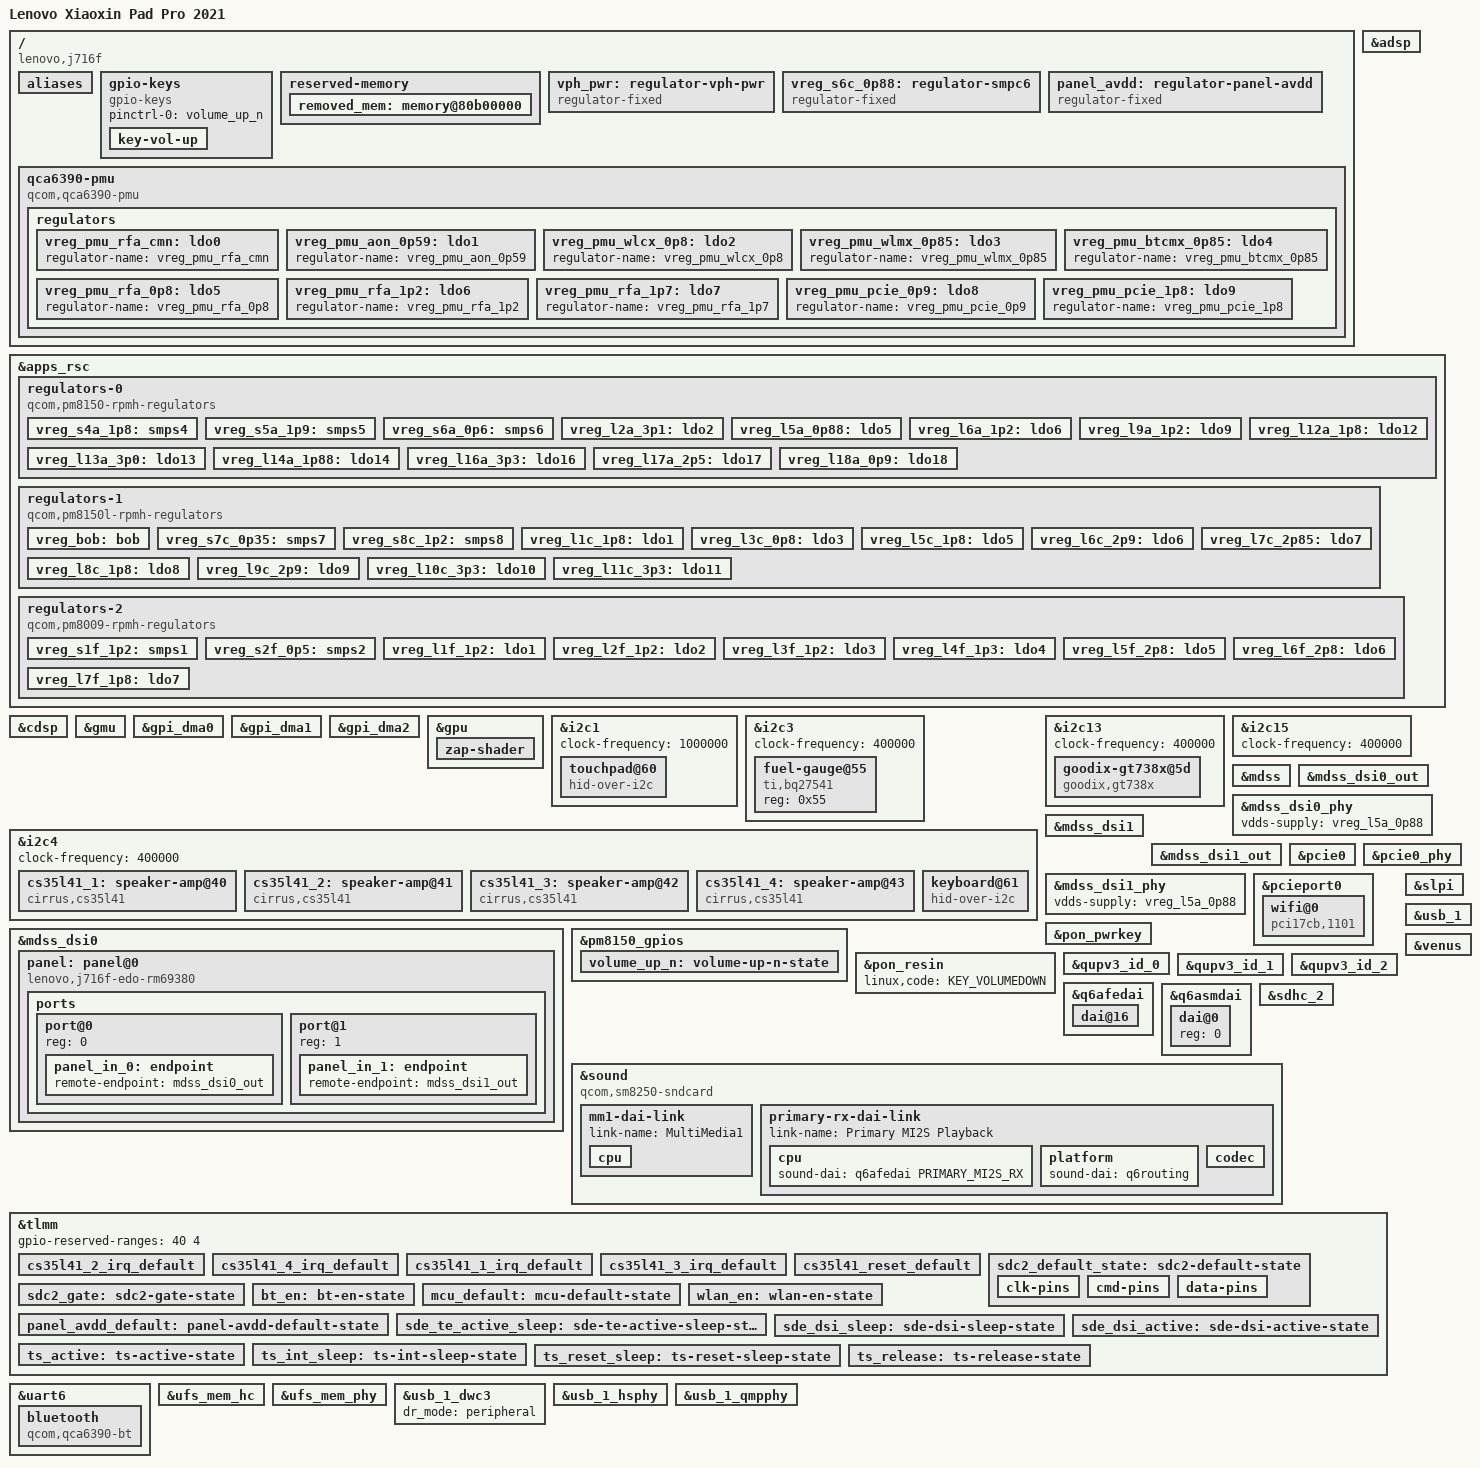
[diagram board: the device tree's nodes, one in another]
// SPDX-License-Identifier: GPL-2.0-only
/*
 * Copyright (c) 2025, David Wronek <david@mainlining.org>
 */

/dts-v1/;

#include <dt-bindings/arm/qcom,ids.h>
#include <dt-bindings/gpio/gpio.h>
#include <dt-bindings/regulator/qcom,rpmh-regulator.h>
#include <dt-bindings/sound/qcom,q6afe.h>
#include <dt-bindings/sound/qcom,q6asm.h>
#include "sm8250.dtsi"
#include "pm8009.dtsi"
#include "pm8150.dtsi"
#include "pm8150l.dtsi"

/ {
	model = "Lenovo Xiaoxin Pad Pro 2021";
	compatible = "lenovo,j716f", "qcom,sm8250";
	chassis-type = "tablet";

	/* required for bootloader to select correct board */
	qcom,msm-id = <QCOM_ID_SM8250 0x20001>; /* SM8250 v2.1 */
	qcom,board-id = <0x2010008 0>;

	aliases {
		mmc0 = &sdhc_2;
		serial0 = &uart6;
	};

	gpio-keys {
		compatible = "gpio-keys";

		pinctrl-names = "default";
		pinctrl-0 = <&volume_up_n>;

		key-vol-up {
			label = "Volume Up";
			linux,code = <KEY_VOLUMEUP>;
			gpios = <&pm8150_gpios 6 GPIO_ACTIVE_LOW>;
			debounce-interval = <15>;
			linux,can-disable;
			wakeup-source;
		};
	};

	reserved-memory {
		removed_mem: memory@80b00000 {
			reg = <0x0 0x80b00000 0x0 0x5700000>;
			no-map;
		};
	};

	vph_pwr: regulator-vph-pwr {
		compatible = "regulator-fixed";

		regulator-name = "vph_pwr";
		regulator-min-microvolt = <3700000>;
		regulator-max-microvolt = <3700000>;
		regulator-always-on;
		regulator-boot-on;
	};

	/* S6c is really ebi.lvl but it's there for supply map completeness sake. */
	vreg_s6c_0p88: regulator-smpc6 {
		compatible = "regulator-fixed";

		regulator-name = "vreg_s6c_0p88";
		regulator-min-microvolt = <880000>;
		regulator-max-microvolt = <880000>;
		regulator-always-on;

		vin-supply = <&vph_pwr>;
	};

	panel_avdd: regulator-panel-avdd {
		compatible = "regulator-fixed";

		regulator-name = "panel_avdd";
		regulator-min-microvolt = "5500000";
		regulator-max-microvolt = "5500000";
		regulator-enable-ramp-delay = <233>;
		regulator-boot-on;

		pinctrl-0 = <&panel_avdd_default>;
		pinctrl-names = "default";

		gpio = <&tlmm 61 GPIO_ACTIVE_HIGH>;
		enable-active-high;
	};

	qca6390-pmu {
		compatible = "qcom,qca6390-pmu";

		pinctrl-names = "default";
		pinctrl-0 = <&bt_en>, <&wlan_en>;

		vddaon-supply = <&vreg_s6a_0p6>;
		vddpmu-supply = <&vreg_s2f_0p5>;
		vddrfa0p95-supply = <&vreg_s6a_0p6>;
		vddrfa1p3-supply = <&vreg_s8c_1p2>;
		vddrfa1p9-supply = <&vreg_s5a_1p9>;
		vddpcie1p3-supply = <&vreg_s8c_1p2>;
		vddpcie1p9-supply = <&vreg_s5a_1p9>;
		vddio-supply = <&vreg_s4a_1p8>;

		wlan-enable-gpios = <&tlmm 20 GPIO_ACTIVE_HIGH>;
		bt-enable-gpios = <&tlmm 21 GPIO_ACTIVE_HIGH>;

		regulators {
			vreg_pmu_rfa_cmn: ldo0 {
				regulator-name = "vreg_pmu_rfa_cmn";
			};

			vreg_pmu_aon_0p59: ldo1 {
				regulator-name = "vreg_pmu_aon_0p59";
			};

			vreg_pmu_wlcx_0p8: ldo2 {
				regulator-name = "vreg_pmu_wlcx_0p8";
			};

			vreg_pmu_wlmx_0p85: ldo3 {
				regulator-name = "vreg_pmu_wlmx_0p85";
			};

			vreg_pmu_btcmx_0p85: ldo4 {
				regulator-name = "vreg_pmu_btcmx_0p85";
			};

			vreg_pmu_rfa_0p8: ldo5 {
				regulator-name = "vreg_pmu_rfa_0p8";
			};

			vreg_pmu_rfa_1p2: ldo6 {
				regulator-name = "vreg_pmu_rfa_1p2";
			};

			vreg_pmu_rfa_1p7: ldo7 {
				regulator-name = "vreg_pmu_rfa_1p7";
			};

			vreg_pmu_pcie_0p9: ldo8 {
				regulator-name = "vreg_pmu_pcie_0p9";
			};

			vreg_pmu_pcie_1p8: ldo9 {
				regulator-name = "vreg_pmu_pcie_1p8";
			};
		};
	};
};

&adsp {
	firmware-name = "qcom/sm8250/LENOVO/J716F/adsp.mbn";
	status = "okay";
};

&apps_rsc {
	regulators-0 {
		compatible = "qcom,pm8150-rpmh-regulators";
		qcom,pmic-id = "a";

		vdd-s1-supply = <&vph_pwr>;
		vdd-s2-supply = <&vph_pwr>;
		vdd-s3-supply = <&vph_pwr>;
		vdd-s4-supply = <&vph_pwr>;
		vdd-s5-supply = <&vph_pwr>;
		vdd-s6-supply = <&vph_pwr>;
		vdd-s7-supply = <&vph_pwr>;
		vdd-s8-supply = <&vph_pwr>;
		vdd-s9-supply = <&vph_pwr>;
		vdd-s10-supply = <&vph_pwr>;
		vdd-l1-l8-l11-supply = <&vreg_s6c_0p88>;
		vdd-l2-l10-supply = <&vreg_bob>;
		vdd-l3-l4-l5-l18-supply = <&vreg_s6a_0p6>;
		vdd-l6-l9-supply = <&vreg_s8c_1p2>;
		vdd-l7-l12-l14-l15-supply = <&vreg_s5a_1p9>;
		vdd-l13-l16-l17-supply = <&vreg_bob>;

		/* (S1+S2+S3) - cx.lvl (ARC) */

		vreg_s4a_1p8: smps4 {
			regulator-name = "vreg_s4a_1p8";
			regulator-min-microvolt = <1800000>;
			regulator-max-microvolt = <1920000>;
			regulator-initial-mode = <RPMH_REGULATOR_MODE_HPM>;
			regulator-allow-set-load;
			regulator-allowed-modes = <RPMH_REGULATOR_MODE_LPM
						   RPMH_REGULATOR_MODE_HPM>;
		};

		vreg_s5a_1p9: smps5 {
			regulator-name = "vreg_s5a_1p9";
			regulator-min-microvolt = <1900000>;
			regulator-max-microvolt = <2040000>;
			regulator-initial-mode = <RPMH_REGULATOR_MODE_HPM>;
		};

		vreg_s6a_0p6: smps6 {
			regulator-name = "vreg_s6a_0p6";
			regulator-min-microvolt = <600000>;
			regulator-max-microvolt = <1128000>;
			regulator-initial-mode = <RPMH_REGULATOR_MODE_HPM>;
		};

		vreg_l2a_3p1: ldo2 {
			regulator-name = "vreg_l2a_3p1";
			regulator-min-microvolt = <3072000>;
			regulator-max-microvolt = <3072000>;
			regulator-initial-mode = <RPMH_REGULATOR_MODE_HPM>;
		};

		/* L3 is unused, L4 - lmx.lvl (ARC) */

		vreg_l5a_0p88: ldo5 {
			regulator-name = "vreg_l5a_0p88";
			regulator-min-microvolt = <880000>;
			regulator-max-microvolt = <880000>;
			regulator-initial-mode = <RPMH_REGULATOR_MODE_HPM>;
		};

		vreg_l6a_1p2: ldo6 {
			regulator-name = "vreg_l6a_1p2";
			regulator-min-microvolt = <1200000>;
			regulator-max-microvolt = <1200000>;
			regulator-initial-mode = <RPMH_REGULATOR_MODE_HPM>;
			regulator-allow-set-load;
			regulator-allowed-modes = <RPMH_REGULATOR_MODE_LPM
						   RPMH_REGULATOR_MODE_HPM>;
		};

		/* L7 is unused. */

		vreg_l9a_1p2: ldo9 {
			regulator-name = "vreg_l9a_1p2";
			regulator-min-microvolt = <1200000>;
			regulator-max-microvolt = <1200000>;
			regulator-initial-mode = <RPMH_REGULATOR_MODE_HPM>;
		};

		/* L10 is unused, L11 - lcx.lvl (ARC) */

		vreg_l12a_1p8: ldo12 {
			regulator-name = "vreg_l12a_1p8";
			regulator-min-microvolt = <1800000>;
			regulator-max-microvolt = <1800000>;
			regulator-initial-mode = <RPMH_REGULATOR_MODE_HPM>;
		};

		vreg_l13a_3p0: ldo13 {
			regulator-name = "vreg_l13a_3p0";
			regulator-min-microvolt = <3008000>;
			regulator-max-microvolt = <3008000>;
			regulator-initial-mode = <RPMH_REGULATOR_MODE_HPM>;
		};

		vreg_l14a_1p88: ldo14 {
			regulator-name = "vreg_l14a_1p88";
			regulator-min-microvolt = <1800000>;
			regulator-max-microvolt = <1880000>;
			regulator-initial-mode = <RPMH_REGULATOR_MODE_HPM>;
		};

		/* L15 is unused. */

		vreg_l16a_3p3: ldo16 {
			regulator-name = "vreg_l16a_3p3";
			regulator-min-microvolt = <3024000>;
			regulator-max-microvolt = <3304000>;
			regulator-initial-mode = <RPMH_REGULATOR_MODE_HPM>;
		};

		vreg_l17a_2p5: ldo17 {
			regulator-name = "vreg_l17a_2p5";
			regulator-min-microvolt = <2496000>;
			regulator-max-microvolt = <3008000>;
			regulator-initial-mode = <RPMH_REGULATOR_MODE_HPM>;
			regulator-allow-set-load;
			regulator-allowed-modes = <RPMH_REGULATOR_MODE_LPM
						   RPMH_REGULATOR_MODE_HPM>;
		};

		vreg_l18a_0p9: ldo18 {
			regulator-name = "vreg_l18a_0p9";
			regulator-min-microvolt = <800000>;
			regulator-max-microvolt = <920000>;
			regulator-initial-mode = <RPMH_REGULATOR_MODE_HPM>;
		};
	};

	/*
	 * Remaining regulators that are not yet supported:
	 * OLEDB: 4925000-8100000
	 * ab: 4600000-6100000
	 * ibb: 800000-5400000
	 */

	regulators-1 {
		compatible = "qcom,pm8150l-rpmh-regulators";
		qcom,pmic-id = "c";

		vdd-s1-supply = <&vph_pwr>;
		vdd-s2-supply = <&vph_pwr>;
		vdd-s3-supply = <&vph_pwr>;
		vdd-s4-supply = <&vph_pwr>;
		vdd-s5-supply = <&vph_pwr>;
		vdd-s6-supply = <&vph_pwr>;
		vdd-s7-supply = <&vph_pwr>;
		vdd-s8-supply = <&vph_pwr>;
		vdd-l1-l8-supply = <&vreg_s4a_1p8>;
		vdd-l2-l3-supply = <&vreg_s8c_1p2>;
		vdd-l4-l5-l6-supply = <&vreg_bob>;
		vdd-l7-l11-supply = <&vreg_bob>;
		vdd-l9-l10-supply = <&vreg_bob>;
		vdd-bob-supply = <&vph_pwr>;

		vreg_bob: bob {
			regulator-name = "vreg_bob";
			regulator-min-microvolt = <3008000>;
			regulator-max-microvolt = <3960000>;
			regulator-initial-mode = <RPMH_REGULATOR_MODE_AUTO>;
		};

		/*
		 * S1-S6 are ARCs:
		 * (S1+S2) - gfx.lvl,
		 * S3 - mx.lvl,
		 * (S4+S5) - mmcx.lvl,
		 * S6 - ebi.lvl
		 */

		vreg_s7c_0p35: smps7 {
			regulator-name = "vreg_s7c_0p35";
			regulator-min-microvolt = <348000>;
			regulator-max-microvolt = <1000000>;
			regulator-initial-mode = <RPMH_REGULATOR_MODE_HPM>;
		};

		vreg_s8c_1p2: smps8 {
			regulator-name = "vreg_s8c_1p2";
			regulator-min-microvolt = <1200000>;
			regulator-max-microvolt = <1400000>;
			regulator-initial-mode = <RPMH_REGULATOR_MODE_HPM>;
		};

		vreg_l1c_1p8: ldo1 {
			regulator-name = "vreg_l1c_1p8";
			regulator-min-microvolt = <1800000>;
			regulator-max-microvolt = <1800000>;
			regulator-initial-mode = <RPMH_REGULATOR_MODE_HPM>;
		};

		/* L2 is unused. */

		vreg_l3c_0p8: ldo3 {
			regulator-name = "vreg_l3c_0p8";
			regulator-min-microvolt = <800000>;
			regulator-max-microvolt = <1200000>;
			regulator-initial-mode = <RPMH_REGULATOR_MODE_HPM>;
		};

		/* L4 is unused. */

		vreg_l5c_1p8: ldo5 {
			regulator-name = "vreg_l5c_1p8";
			regulator-min-microvolt = <1800000>;
			regulator-max-microvolt = <2800000>;
			regulator-initial-mode = <RPMH_REGULATOR_MODE_HPM>;
		};

		vreg_l6c_2p9: ldo6 {
			regulator-name = "vreg_l6c_2p9";
			regulator-min-microvolt = <1800000>;
			regulator-max-microvolt = <2960000>;
			regulator-initial-mode = <RPMH_REGULATOR_MODE_HPM>;
			regulator-allow-set-load;
			regulator-allowed-modes = <RPMH_REGULATOR_MODE_LPM
						   RPMH_REGULATOR_MODE_HPM>;
			/* Broken hw, this one can't be turned off or SDHCI will break! */
			regulator-always-on;
		};

		vreg_l7c_2p85: ldo7 {
			regulator-name = "vreg_l7c_2p85";
			regulator-min-microvolt = <2856000>;
			regulator-max-microvolt = <3104000>;
			regulator-initial-mode = <RPMH_REGULATOR_MODE_HPM>;
		};

		vreg_l8c_1p8: ldo8 {
			regulator-name = "vreg_l8c_1p8";
			regulator-min-microvolt = <1800000>;
			regulator-max-microvolt = <1800000>;
			regulator-initial-mode = <RPMH_REGULATOR_MODE_HPM>;
		};

		vreg_l9c_2p9: ldo9 {
			regulator-name = "vreg_l9c_2p9";
			regulator-min-microvolt = <2704000>;
			regulator-max-microvolt = <2960000>;
			regulator-initial-mode = <RPMH_REGULATOR_MODE_HPM>;
			regulator-allow-set-load;
			regulator-allowed-modes = <RPMH_REGULATOR_MODE_LPM
						   RPMH_REGULATOR_MODE_HPM>;
			/* Broken hw, this one can't be turned off or SDHCI will break! */
			regulator-always-on;
		};

		vreg_l10c_3p3: ldo10 {
			regulator-name = "vreg_l10c_3p3";
			regulator-min-microvolt = <3000000>;
			regulator-max-microvolt = <3312000>;
			regulator-initial-mode = <RPMH_REGULATOR_MODE_HPM>;
		};

		vreg_l11c_3p3: ldo11 {
			regulator-name = "vreg_l11c_3p0";
			regulator-min-microvolt = <3104000>;
			regulator-max-microvolt = <3304000>;
			regulator-initial-mode = <RPMH_REGULATOR_MODE_HPM>;
		};
	};

	regulators-2 {
		compatible = "qcom,pm8009-rpmh-regulators";
		qcom,pmic-id = "f";

		vdd-s1-supply = <&vph_pwr>;
		vdd-s2-supply = <&vreg_bob>;
		vdd-l2-supply = <&vreg_s8c_1p2>;
		vdd-l5-l6-supply = <&vreg_bob>;
		vdd-l7-supply = <&vreg_s4a_1p8>;

		vreg_s1f_1p2: smps1 {
			regulator-name = "vreg_s1f_1p2";
			regulator-min-microvolt = <1200000>;
			regulator-max-microvolt = <1200000>;
			regulator-initial-mode = <RPMH_REGULATOR_MODE_HPM>;
		};

		vreg_s2f_0p5: smps2 {
			regulator-name = "vreg_s2f_0p5";
			regulator-min-microvolt = <512000>;
			regulator-max-microvolt = <1100000>;
			regulator-initial-mode = <RPMH_REGULATOR_MODE_HPM>;
		};

		vreg_l1f_1p2: ldo1 {
			regulator-name = "vreg_l1f_1p2";
			regulator-min-microvolt = <1104000>;
			regulator-max-microvolt = <1200000>;
			regulator-initial-mode = <RPMH_REGULATOR_MODE_HPM>;
		};

		vreg_l2f_1p2: ldo2 {
			regulator-name = "vreg_l2f_1p1";
			regulator-min-microvolt = <1200000>;
			regulator-max-microvolt = <1200000>;
			regulator-initial-mode = <RPMH_REGULATOR_MODE_HPM>;
		};

		vreg_l3f_1p2: ldo3 {
			regulator-name = "vreg_l3f_1p2";
			regulator-min-microvolt = <1056000>;
			regulator-max-microvolt = <1200000>;
			regulator-initial-mode = <RPMH_REGULATOR_MODE_HPM>;
		};

		vreg_l4f_1p3: ldo4 {
			regulator-name = "vreg_l4f_1p3";
			regulator-min-microvolt = <1096000>;
			regulator-max-microvolt = <1304000>;
			regulator-initial-mode = <RPMH_REGULATOR_MODE_HPM>;
		};

		vreg_l5f_2p8: ldo5 {
			regulator-name = "vreg_l5f_2p85";
			regulator-min-microvolt = <2800000>;
			regulator-max-microvolt = <3000000>;
			regulator-initial-mode = <RPMH_REGULATOR_MODE_HPM>;
		};

		vreg_l6f_2p8: ldo6 {
			regulator-name = "vreg_l6f_2p8";
			regulator-min-microvolt = <2800000>;
			regulator-max-microvolt = <3000000>;
			regulator-initial-mode = <RPMH_REGULATOR_MODE_HPM>;
		};

		vreg_l7f_1p8: ldo7 {
			regulator-name = "vreg_l7f_1p8";
			regulator-min-microvolt = <1800000>;
			regulator-max-microvolt = <1800000>;
			regulator-initial-mode = <RPMH_REGULATOR_MODE_HPM>;
		};
	};
};

&cdsp {
	firmware-name = "qcom/sm8250/LENOVO/J716F/cdsp.mbn";
	status = "okay";
};

&gmu {
	status = "okay";
};

&gpi_dma0 {
	status = "okay";
};

&gpi_dma1 {
	status = "okay";
};

&gpi_dma2 {
	status = "okay";
};

&gpu {
	status = "okay";

	zap-shader {
		memory-region = <&gpu_mem>;
		firmware-name = "qcom/sm8250/LENOVO/J716F/a650_zap.mbn";
	};
};

&i2c1 {
	clock-frequency = <1000000>;
	status = "okay";

	touchpad@60 {
		compatible = "hid-over-i2c";
		reg = <0x60>;

		vdd-supply = <&vreg_l16a_3p3>;
		vddl-supply = <&vreg_l8c_1p8>;

		interrupt-parent = <&tlmm>;
		interrupts = <14 IRQ_TYPE_LEVEL_LOW>;

		hid-descr-addr = <0x01>;
		post-power-on-delay-ms = <100>;
	};
};

&i2c3 {
	clock-frequency = <400000>;
	status = "okay";

	fuel-gauge@55 {
		compatible = "ti,bq27541";
		reg = <0x55>;
	};
};

&i2c4 {
	clock-frequency = <400000>;
	status = "okay";

	/* onsemi NB7VPQ904M USB redriver @ 19 */

	//left-down-speaker
	cs35l41_1: speaker-amp@40 {
		compatible = "cirrus,cs35l41";
		reg = <0x40>;
		pinctrl-names = "default";
		pinctrl-0 = <&cs35l41_1_irq_default>;
		VA-supply = <&vreg_l16a_3p3>;
		interrupt-parent = <&tlmm>;
		interrupts = <67 IRQ_TYPE_LEVEL_LOW>;
		reset-gpios = <&tlmm 131 GPIO_ACTIVE_HIGH>;
		cirrus,boost-type = <0>;
		cirrus,boost-peak-milliamp = <3500>;
		cirrus,boost-ind-nanohenry = <1000>;
		cirrus,boost-cap-microfarad = <15>;
		cirrus,asp-sdout-hiz = <3>;
		cirrus,gpio2-src-select = <4>;
		cirrus,gpio2-output-enable;
		sound-name-prefix = "SPK1";
		#sound-dai-cells = <1>;
	};

	//right-down-speaker
	cs35l41_2: speaker-amp@41 {
		compatible = "cirrus,cs35l41";
		reg = <0x41>;
		pinctrl-names = "default";
		pinctrl-0 = <&cs35l41_2_irq_default>;
		VA-supply = <&vreg_l16a_3p3>;
		interrupt-parent = <&tlmm>;
		interrupts = <113 IRQ_TYPE_LEVEL_LOW>;
		reset-gpios = <&tlmm 131 GPIO_ACTIVE_HIGH>;
		cirrus,boost-type = <0>;
		cirrus,boost-peak-milliamp = <3500>;
		cirrus,boost-ind-nanohenry = <1000>;
		cirrus,boost-cap-microfarad = <15>;
		cirrus,asp-sdout-hiz = <3>;
		cirrus,gpio2-src-select = <4>;
		cirrus,gpio2-output-enable;
		sound-name-prefix = "SPK2";
		#sound-dai-cells = <1>;
	};

	//right-up-speaker
	cs35l41_3: speaker-amp@42 {
		compatible = "cirrus,cs35l41";
		reg = <0x42>;
		pinctrl-names = "default";
		pinctrl-0 = <&cs35l41_3_irq_default>;
		VA-supply = <&vreg_l16a_3p3>;
		interrupt-parent = <&tlmm>;
		interrupts = <126 IRQ_TYPE_LEVEL_LOW>;
		reset-gpios = <&tlmm 131 GPIO_ACTIVE_HIGH>;
		cirrus,boost-type = <0>;
		cirrus,boost-peak-milliamp = <3500>;
		cirrus,boost-ind-nanohenry = <1000>;
		cirrus,boost-cap-microfarad = <15>;
		cirrus,asp-sdout-hiz = <3>;
		cirrus,gpio2-src-select = <4>;
		cirrus,gpio2-output-enable;
		sound-name-prefix = "SPK3";
		#sound-dai-cells = <1>;
	};

	//left-up-speaker
	cs35l41_4: speaker-amp@43 {
		compatible = "cirrus,cs35l41";
		reg = <0x43>;
		pinctrl-names = "default";
		pinctrl-0 = <&cs35l41_4_irq_default>;
		VA-supply = <&vreg_l16a_3p3>;
		interrupt-parent = <&tlmm>;
		interrupts = <68 IRQ_TYPE_LEVEL_LOW>;
		reset-gpios = <&tlmm 131 GPIO_ACTIVE_HIGH>;
		cirrus,boost-type = <0>;
		cirrus,boost-peak-milliamp = <3500>;
		cirrus,boost-ind-nanohenry = <1000>;
		cirrus,boost-cap-microfarad = <15>;
		cirrus,asp-sdout-hiz = <3>;
		cirrus,gpio2-src-select = <4>;
		cirrus,gpio2-output-enable;
		sound-name-prefix = "SPK4";
		#sound-dai-cells = <1>;
	};

	keyboard@61 {
		compatible = "hid-over-i2c";
		reg = <0x61>;

		vdd-supply = <&vreg_l16a_3p3>;
		vddl-supply = <&vreg_l8c_1p8>;

		pinctrl-names = "default";
		pinctrl-0 = <&mcu_default>;

		interrupt-parent = <&tlmm>;
		interrupts = <11 IRQ_TYPE_LEVEL_LOW>;

		hid-descr-addr = <0x1>;
		post-power-on-delay-ms = <100>;
	};
};

&i2c13 {
	clock-frequency = <400000>;
	status = "okay";

	goodix-gt738x@5d {
		compatible = "goodix,gt738x";
		reg = <0x5d>;

		goodix,reset-gpio = <&tlmm 38 0>;
		goodix,irq-gpio = <&tlmm 39 0x2008>;
		goodix,irq-flags = <0x2>;
		goodix,panel-max-x = <2560>;
		goodix,panel-max-y = <1600>;
		goodix,panel-max-w = <2368>;
		goodix,vdd-name = "vdd";
		goodix,avdd-name = "avdd";
		goodix,vddio-name = "vddio";
		goodix,swap-axis = <1>;
		goodix,x2x = <1>;

		vdd-supply = <&vreg_l1c_1p8>;
		vddio-supply = <&vreg_l14a_1p88>;
		avdd-supply = <&vreg_l13a_3p0>;

		pinctrl-names = "ts_active", "ts_sleep", "ts_release";
		pinctrl-0 = <&ts_active>;
		pinctrl-1 = <&ts_int_sleep &ts_reset_sleep>;
		pinctrl-2 = <&ts_release>;

		panel = <&panel>;
	};
};

&i2c15 {
	clock-frequency = <400000>;
	status = "okay";

	/* SMB1390 charger @ 10 */
	/* ES7210 audio ADC @ 40 */
	/* FSA4480 USB audio switch @ 43 */
	/* RTC6226 FM receiver @ 64 */
	/* HL6111R wireless charging IC @ 25 */
};

&mdss {
	status = "okay";
};

&mdss_dsi0 {
	vdda-supply = <&vreg_l9a_1p2>;
	qcom,dual-dsi-mode;
	qcom,sync-dual-dsi;
	qcom,master-dsi;

	status = "okay";

	panel: panel@0 {
		compatible = "lenovo,j716f-edo-rm69380", "raydium,rm69380";
		reg = <0>;

		vddio-supply = <&vreg_l14a_1p88>;
		avdd-supply = <&panel_avdd>;
		reset-gpios = <&tlmm 75 GPIO_ACTIVE_LOW>;

		pinctrl-0 = <&sde_dsi_active &sde_te_active_sleep>;
		pinctrl-1 = <&sde_dsi_sleep &sde_te_active_sleep>;
		pinctrl-names = "default", "sleep";

		ports {
			#address-cells = <1>;
			#size-cells = <0>;

			port@0 {
				reg = <0>;

				panel_in_0: endpoint {
					remote-endpoint = <&mdss_dsi0_out>;
				};
			};

			port@1 {
				reg = <1>;

				panel_in_1: endpoint {
					remote-endpoint = <&mdss_dsi1_out>;
				};
			};
		};
	};
};

&mdss_dsi0_out {
	remote-endpoint = <&panel_in_0>;
	data-lanes = <0 1 2 3>;
};

&mdss_dsi0_phy {
	vdds-supply = <&vreg_l5a_0p88>;
	status = "okay";
};

&mdss_dsi1 {
	vdda-supply = <&vreg_l9a_1p2>;
	qcom,dual-dsi-mode;
	qcom,sync-dual-dsi;
	status = "okay";
};

&mdss_dsi1_out {
	remote-endpoint = <&panel_in_1>;
	data-lanes = <0 1 2 3>;
};

&mdss_dsi1_phy {
	vdds-supply = <&vreg_l5a_0p88>;
	status = "okay";
};

&pcie0 {
	status = "okay";
};

&pcie0_phy {
	vdda-phy-supply = <&vreg_l5a_0p88>;
	vdda-pll-supply = <&vreg_l9a_1p2>;
	status = "okay";
};

&pcieport0 {
	wifi@0 {
		compatible = "pci17cb,1101";
		reg = <0x10000 0x0 0x0 0x0 0x0>;

		vddrfacmn-supply = <&vreg_pmu_rfa_cmn>;
		vddaon-supply = <&vreg_pmu_aon_0p59>;
		vddwlcx-supply = <&vreg_pmu_wlcx_0p8>;
		vddwlmx-supply = <&vreg_pmu_wlmx_0p85>;
		vddrfa0p8-supply = <&vreg_pmu_rfa_0p8>;
		vddrfa1p2-supply = <&vreg_pmu_rfa_1p2>;
		vddrfa1p7-supply = <&vreg_pmu_rfa_1p7>;
		vddpcie0p9-supply = <&vreg_pmu_pcie_0p9>;
		vddpcie1p8-supply = <&vreg_pmu_pcie_1p8>;
	};
};

&pm8150_gpios {
	volume_up_n: volume-up-n-state {
		pins = "gpio6";
		function = "normal";
		bias-pull-up;
		input-enable;
		power-source = <1>;
	};
};

&pon_pwrkey {
	status = "okay";
};

&pon_resin {
	linux,code = <KEY_VOLUMEDOWN>;
	status = "okay";
};

&qupv3_id_0 {
	status = "okay";
};

&qupv3_id_1 {
	status = "okay";
};

&qupv3_id_2 {
	status = "okay";
};

&q6afedai {
	dai@16 {
		reg = <PRIMARY_MI2S_RX>;
		qcom,sd-lines = <1>;
	};
};

&q6asmdai {
	dai@0 {
		reg = <0>;
	};
};

&sdhc_2 {
	cd-gpios = <&tlmm 77 GPIO_ACTIVE_HIGH>;
	pinctrl-names = "default", "sleep";
	pinctrl-0 = <&sdc2_default_state &sdc2_gate>;
	pinctrl-1 = <&sdc2_sleep_state &sdc2_gate>;
	vmmc-supply = <&vreg_l9c_2p9>;
	vqmmc-supply = <&vreg_l6c_2p9>;
	no-sdio;
	no-mmc;
	status = "okay";
};

&slpi {
	firmware-name = "qcom/sm8250/LENOVO/J716F/slpi.mbn";
	status = "okay";
};

&sound {
	compatible = "qcom,sm8250-sndcard";
	model = "Lenovo Xiaoxin Pad Pro 2021";
	pinctrl-names = "default";
	pinctrl-0 = <&pri_mi2s_active>;

	mm1-dai-link {
		link-name = "MultiMedia1";

		cpu {
			sound-dai = <&q6asmdai MSM_FRONTEND_DAI_MULTIMEDIA1>;
		};
	};

	primary-rx-dai-link {
		link-name = "Primary MI2S Playback";

		cpu {
			sound-dai = <&q6afedai PRIMARY_MI2S_RX>;
		};

		platform {
			sound-dai = <&q6routing>;
		};

		codec {
			sound-dai = <&cs35l41_1 0>, <&cs35l41_2 0>,
				    <&cs35l41_3 0>, <&cs35l41_4 0>;
		};
	};
};

&tlmm {
	gpio-reserved-ranges = <40 4>;

	cs35l41_2_irq_default: cs35l41_2_irq_default {
		pins = "gpio113";
		function = "gpio";
		drive-strength = <2>;
		bias-pull-up;
	};

	cs35l41_4_irq_default: cs35l41_4_irq_default {
		pins = "gpio68";
		function = "gpio";
		drive-strength = <2>;
		bias-pull-up;
	};

	cs35l41_1_irq_default: cs35l41_1_irq_default {
		pins = "gpio67";
		function = "gpio";
		drive-strength = <2>;
		bias-pull-up;
	};

	cs35l41_3_irq_default: cs35l41_3_irq_default {
		pins = "gpio126";
		function = "gpio";
		drive-strength = <2>;
		bias-pull-up;
	};

	cs35l41_reset_default: cs35l41_reset_default {
		pins = "gpio131";
		function = "gpio";
		output-high;
		bias-pull-up;
		drive-strength = <16>;
	};

	sdc2_default_state: sdc2-default-state {
		clk-pins {
			pins = "sdc2_clk";
			drive-strength = <16>;
			bias-disable;
		};

		cmd-pins {
			pins = "sdc2_cmd";
			drive-strength = <16>;
			bias-pull-up;
		};

		data-pins {
			pins = "sdc2_data";
			drive-strength = <16>;
			bias-pull-up;
		};
	};

	sdc2_gate: sdc2-gate-state {
		pins = "gpio116";
		function = "gpio";
		drive-strength = <2>;
		bias-pull-up;
		output-high;
	};

	bt_en: bt-en-state {
		pins = "gpio21";
		function = "gpio";
		drive-strength = <16>;
		output-low;
		bias-pull-up;
	};

	mcu_default: mcu-default-state {
		pins = "gpio11", "gpio14", "gpio25";
		function = "gpio";
		bias-disable;
	};

	wlan_en: wlan-en-state {
		pins = "gpio20";
		function = "gpio";
		drive-strength = <16>;
		output-low;
		bias-pull-up;
	};

	panel_avdd_default: panel-avdd-default-state {
		pins = "gpio61";
		function = "gpio";
		drive-strength = <8>;
		bias-disable;
		output-high;
	};

	sde_te_active_sleep: sde-te-active-sleep-state {
		pins = "gpio66";
		function = "mdp_vsync";
		drive-strength = <2>;
		bias-pull-down;
	};

	sde_dsi_sleep: sde-dsi-sleep-state {
		pins = "gpio75";
		function = "gpio";
		drive-strength = <2>;
		bias-pull-down;
		output-high;
	};

	sde_dsi_active: sde-dsi-active-state {
		pins = "gpio75";
		function = "gpio";
		drive-strength = <8>;
		bias-disable;
		output-high;
	};

	ts_active: ts-active-state {
		pins = "gpio38", "gpio39";
		function = "gpio";
		drive-strength = <8>;
		bias-pull-up;
	};

	ts_int_sleep: ts-int-sleep-state {
		pins = "gpio39";
		function = "gpio";
		drive-strength = <2>;
		bias-pull-down;
	};

	ts_reset_sleep: ts-reset-sleep-state {
		pins = "gpio38";
		function = "gpio";
		drive-strength = <2>;
		bias-pull-down;
	};

	ts_release: ts-release-state {
		pins = "gpio38", "gpio39";
		function = "gpio";
		drive-strength = <2>;
		bias-disable;
	};
};

&uart6 {
	status = "okay";

	bluetooth {
		compatible = "qcom,qca6390-bt";

		vddrfacmn-supply = <&vreg_pmu_rfa_cmn>;
		vddaon-supply = <&vreg_pmu_aon_0p59>;
		vddbtcmx-supply = <&vreg_pmu_btcmx_0p85>;
		vddrfa0p8-supply = <&vreg_pmu_rfa_0p8>;
		vddrfa1p2-supply = <&vreg_pmu_rfa_1p2>;
		vddrfa1p7-supply = <&vreg_pmu_rfa_1p7>;
	};
};

&ufs_mem_hc {
	vcc-supply = <&vreg_l17a_2p5>;
	vcc-max-microamp = <800000>;
	vccq-supply = <&vreg_l6a_1p2>;
	vccq-max-microamp = <800000>;
	vccq2-supply = <&vreg_s4a_1p8>;
	vccq2-max-microamp = <800000>;

	status = "okay";
};

&ufs_mem_phy {
	vdda-phy-supply = <&vreg_l5a_0p88>;
	vdda-pll-supply = <&vreg_l9a_1p2>;

	status = "okay";
};

&usb_1 {
	status = "okay";
};

&usb_1_dwc3 {
	dr_mode = "peripheral";
};

&usb_1_hsphy {
	vdda-pll-supply = <&vreg_l5a_0p88>;
	vdda18-supply = <&vreg_l12a_1p8>;
	vdda33-supply = <&vreg_l2a_3p1>;

	status = "okay";
};

&usb_1_qmpphy {
	vdda-phy-supply = <&vreg_l9a_1p2>;
	vdda-pll-supply = <&vreg_l18a_0p9>;

	status = "okay";
};

&venus {
	firmware-name = "qcom/sm8250/LENOVO/J716F/venus.mbn";
	status = "okay";
};
